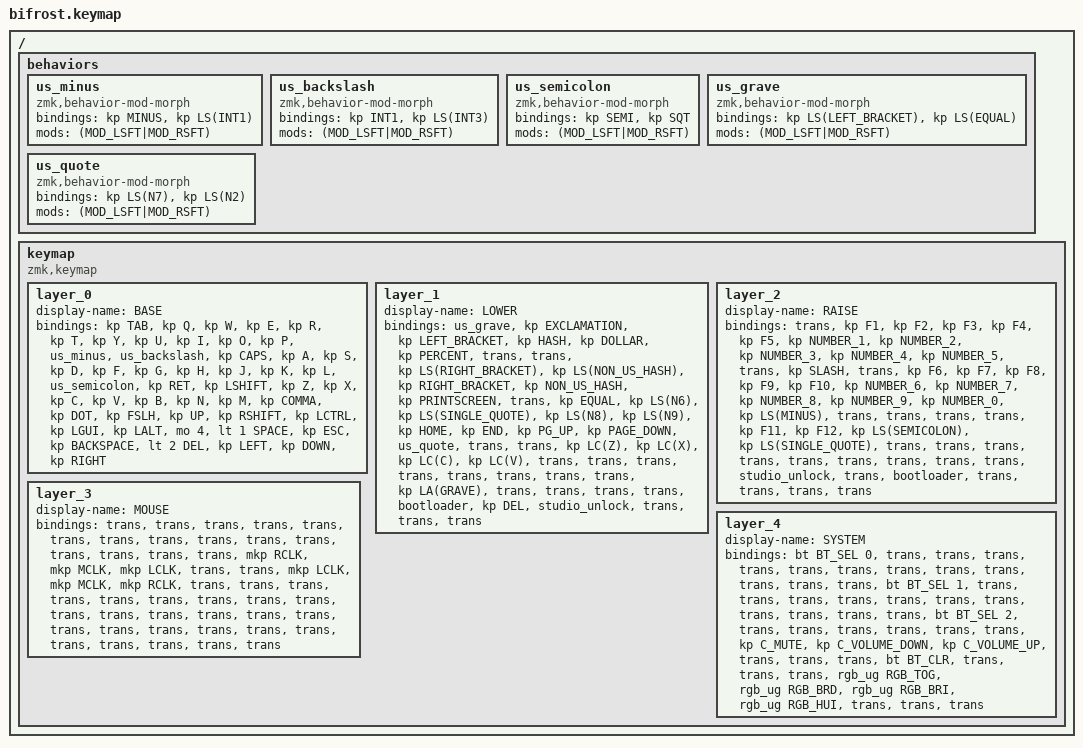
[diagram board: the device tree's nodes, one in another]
/*
 * Copyright (c) 2026 hringdrifi
 * SPDX-License-Identifier: MIT
 */

#include <dt-bindings/zmk/modifiers.h>
#include <behaviors.dtsi>
#include <dt-bindings/zmk/bt.h>
#include <dt-bindings/zmk/keys.h>
#include <dt-bindings/zmk/pointing.h>
#include <dt-bindings/zmk/rgb.h>

#define LOWER 1
#define RAISE 2
#define MOUSE 3
#define SYSTEM 4

/ {
    /* Windows JIS host: emit the keys that produce US-layout symbols. */

    behaviors {
        us_minus: us_minus {
            compatible = "zmk,behavior-mod-morph";
            #binding-cells = <0>;
            bindings = <&kp MINUS>, <&kp LS(INT1)>;

            mods = <(MOD_LSFT|MOD_RSFT)>;
        };

        us_backslash: us_backslash {
            compatible = "zmk,behavior-mod-morph";
            #binding-cells = <0>;
            bindings = <&kp INT1>, <&kp LS(INT3)>;

            mods = <(MOD_LSFT|MOD_RSFT)>;
        };

        us_semicolon: us_semicolon {
            compatible = "zmk,behavior-mod-morph";
            #binding-cells = <0>;
            bindings = <&kp SEMI>, <&kp SQT>;

            mods = <(MOD_LSFT|MOD_RSFT)>;
        };

        us_grave: us_grave {
            compatible = "zmk,behavior-mod-morph";
            #binding-cells = <0>;
            bindings = <&kp LS(LEFT_BRACKET)>, <&kp LS(EQUAL)>;

            mods = <(MOD_LSFT|MOD_RSFT)>;
        };

        us_quote: us_quote {
            compatible = "zmk,behavior-mod-morph";
            #binding-cells = <0>;
            bindings = <&kp LS(N7)>, <&kp LS(N2)>;

            mods = <(MOD_LSFT|MOD_RSFT)>;
        };
    };

    keymap {
        compatible = "zmk,keymap";

        /* Base: familiar QWERTY with dedicated shifts and thumb layers. */

        layer_0 {
            display-name = "BASE";
            bindings = <
&kp TAB  &kp Q  &kp W  &kp E  &kp R  &kp T  &kp Y  &kp U  &kp I  &kp O  &kp P  &us_minus  &us_backslash  &kp CAPS  &kp A  &kp S  &kp D  &kp F  &kp G  &kp H  &kp J  &kp K  &kp L  &us_semicolon  &kp RET  &kp LSHIFT  &kp Z  &kp X  &kp C  &kp V  &kp B  &kp N  &kp M  &kp COMMA  &kp DOT  &kp FSLH  &kp UP  &kp RSHIFT  &kp LCTRL  &kp LGUI  &kp LALT  &mo 4  &lt 1 SPACE  &kp ESC  &kp BACKSPACE  &lt 2 DEL  &kp LEFT  &kp DOWN  &kp RIGHT
            >;
        };

        /*
         * Lower: symbols (JIS keycodes for US-layout characters), navigation,
         * editing shortcuts, and IME toggle (Alt+Hankaku/Zenkaku).
         */

        layer_1 {
            display-name = "LOWER";
            bindings = <
&us_grave  &kp EXCLAMATION  &kp LEFT_BRACKET  &kp HASH  &kp DOLLAR  &kp PERCENT  &trans  &trans  &kp LS(RIGHT_BRACKET)  &kp LS(NON_US_HASH)  &kp RIGHT_BRACKET  &kp NON_US_HASH  &kp PRINTSCREEN  &trans  &kp EQUAL  &kp LS(N6)  &kp LS(SINGLE_QUOTE)  &kp LS(N8)  &kp LS(N9)  &kp HOME  &kp END  &kp PG_UP  &kp PAGE_DOWN  &us_quote  &trans  &trans  &kp LC(Z)  &kp LC(X)  &kp LC(C)  &kp LC(V)  &trans  &trans  &trans  &trans  &trans  &trans  &trans  &trans  &kp LA(GRAVE)  &trans  &trans  &trans  &trans  &bootloader  &kp DEL  &studio_unlock  &trans  &trans  &trans
            >;
        };

        /* Raise: function keys, numbers, and arithmetic symbols. */

        layer_2 {
            display-name = "RAISE";
            bindings = <
&trans  &kp F1  &kp F2  &kp F3  &kp F4  &kp F5  &kp NUMBER_1  &kp NUMBER_2  &kp NUMBER_3  &kp NUMBER_4  &kp NUMBER_5  &trans  &kp SLASH  &trans  &kp F6  &kp F7  &kp F8  &kp F9  &kp F10  &kp NUMBER_6  &kp NUMBER_7  &kp NUMBER_8  &kp NUMBER_9  &kp NUMBER_0  &kp LS(MINUS)  &trans  &trans  &trans  &trans  &kp F11  &kp F12  &kp LS(SEMICOLON)  &kp LS(SINGLE_QUOTE)  &trans  &trans  &trans  &trans  &trans  &trans  &trans  &trans  &trans  &studio_unlock  &trans  &bootloader  &trans  &trans  &trans  &trans
            >;
        };

        /* Mouse: auto-activated by trackball movement; clicks on home row. */

        layer_3 {
            display-name = "MOUSE";
            bindings = <
&trans  &trans  &trans  &trans  &trans  &trans  &trans  &trans  &trans  &trans  &trans  &trans  &trans  &trans  &trans  &mkp RCLK  &mkp MCLK  &mkp LCLK  &trans  &trans  &mkp LCLK  &mkp MCLK  &mkp RCLK  &trans  &trans  &trans  &trans  &trans  &trans  &trans  &trans  &trans  &trans  &trans  &trans  &trans  &trans  &trans  &trans  &trans  &trans  &trans  &trans  &trans  &trans  &trans  &trans  &trans  &trans
            >;
        };

        /* System: Bluetooth profiles, media volume, and underglow controls. */

        layer_4 {
            display-name = "SYSTEM";
            bindings = <
&bt BT_SEL 0  &trans  &trans  &trans  &trans  &trans  &trans  &trans  &trans  &trans  &trans  &trans  &trans  &bt BT_SEL 1  &trans  &trans  &trans  &trans  &trans  &trans  &trans  &trans  &trans  &trans  &trans  &bt BT_SEL 2  &trans  &trans  &trans  &trans  &trans  &trans  &kp C_MUTE  &kp C_VOLUME_DOWN  &kp C_VOLUME_UP  &trans  &trans  &trans  &bt BT_CLR  &trans  &trans  &trans  &rgb_ug RGB_TOG  &rgb_ug RGB_BRD  &rgb_ug RGB_BRI  &rgb_ug RGB_HUI  &trans  &trans  &trans
            >;
        };
    };
};
